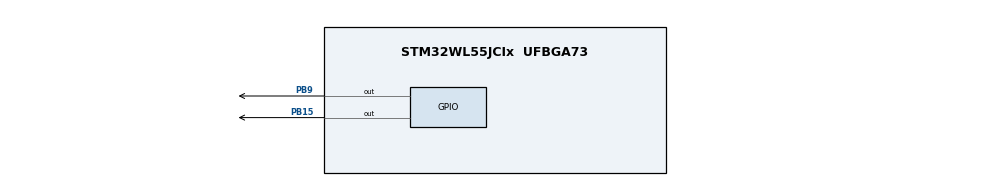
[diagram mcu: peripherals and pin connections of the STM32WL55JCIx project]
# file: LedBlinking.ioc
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Mcu.Family=STM32WL
Mcu.Name=STM32WL55JCIx
Mcu.Package=UFBGA73
NVIC.PriorityGroup=NVIC_PRIORITYGROUP_4
PB15.GPIO_Speed=GPIO_SPEED_FREQ_LOW
PB15.Signal=GPIO_Output
PB3.Signal=SPI1_SCK
PB9.Signal=GPIO_Output
ProjectManager.HeapSize=0x200
ProjectManager.StackSize=0x400
ProjectManager.TargetToolchain=STM32CubeIDE
RCC.AHBFreq_Value=48000000
RCC.APB1Freq_Value=48000000
RCC.APB1TimFreq_Value=48000000
RCC.APB2Freq_Value=48000000
RCC.APB2TimFreq_Value=48000000
RCC.APB3Freq_Value=48000000
RCC.CortexFreq_Value=48000000
RCC.HCLKFreq_Value=48000000
RCC.HSE_VALUE=8000000
RCC.HSI_VALUE=16000000
RCC.LSE_VALUE=32768
RCC.MSIClockRange=RCC_MSIRANGE_11
RCC.SYSCLKFreq_VALUE=48000000
RCC.VCOOutputFreq_Value=384000000
board=custom

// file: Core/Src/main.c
/* USER CODE BEGIN Header */
/**
  ******************************************************************************
  * @file           : main.c
  * @brief          : Main program body
  ******************************************************************************
  * @attention
  *
  * <h2><center>&copy; Copyright (c) 2021 STMicroelectronics.
  * All rights reserved.</center></h2>
  *
  * This software component is licensed by ST under BSD 3-Clause license,
  * the "License"; You may not use this file except in compliance with the
  * License. You may obtain a copy of the License at:
  *                        opensource.org/licenses/BSD-3-Clause
  *
  ******************************************************************************
  */
/* USER CODE END Header */
#include "main.h"

void SystemClock_Config(void);
static void MX_GPIO_Init(void);

int main(void)
{

  /* MCU Configuration--------------------------------------------------------*/

  /* Reset of all peripherals, Initializes the Flash interface and the Systick. */
  HAL_Init();

  /* Configure the system clock */
  SystemClock_Config();

  /* Initialize all configured peripherals */
  MX_GPIO_Init();

  /* Infinite loop */
  while (1)
  {

    /* USER CODE BEGIN 3 */

	HAL_GPIO_TogglePin(GPIOB,GPIO_PIN_15);
	HAL_GPIO_TogglePin(GPIOB,GPIO_PIN_9);
	HAL_Delay(500);
  }
  /* USER CODE END 3 */
}

void SystemClock_Config(void)
{
  RCC_OscInitTypeDef RCC_OscInitStruct = {0};
  RCC_ClkInitTypeDef RCC_ClkInitStruct = {0};

  /** Configure the main internal regulator output voltage
  */
  __HAL_PWR_VOLTAGESCALING_CONFIG(PWR_REGULATOR_VOLTAGE_SCALE1);
  /** Initializes the CPU, AHB and APB busses clocks
  */
  RCC_OscInitStruct.OscillatorType = RCC_OSCILLATORTYPE_MSI;
  RCC_OscInitStruct.MSIState = RCC_MSI_ON;
  RCC_OscInitStruct.MSICalibrationValue = RCC_MSICALIBRATION_DEFAULT;
  RCC_OscInitStruct.MSIClockRange = RCC_MSIRANGE_11;
  RCC_OscInitStruct.PLL.PLLState = RCC_PLL_NONE;
  if (HAL_RCC_OscConfig(&RCC_OscInitStruct) != HAL_OK)
  {
    Error_Handler();
  }
  /** Configure the SYSCLKSource, HCLK, PCLK1 and PCLK2 clocks dividers
  */
  RCC_ClkInitStruct.ClockType = RCC_CLOCKTYPE_HCLK3|RCC_CLOCKTYPE_HCLK
                              |RCC_CLOCKTYPE_SYSCLK|RCC_CLOCKTYPE_PCLK1
                              |RCC_CLOCKTYPE_PCLK2;
  RCC_ClkInitStruct.SYSCLKSource = RCC_SYSCLKSOURCE_MSI;
  RCC_ClkInitStruct.AHBCLKDivider = RCC_SYSCLK_DIV1;
  RCC_ClkInitStruct.APB1CLKDivider = RCC_HCLK_DIV1;
  RCC_ClkInitStruct.APB2CLKDivider = RCC_HCLK_DIV1;
  RCC_ClkInitStruct.AHBCLK3Divider = RCC_SYSCLK_DIV1;

  if (HAL_RCC_ClockConfig(&RCC_ClkInitStruct, FLASH_LATENCY_2) != HAL_OK)
  {
    Error_Handler();
  }
}

static void MX_GPIO_Init(void)
{
  GPIO_InitTypeDef GPIO_InitStruct = {0};

  /* GPIO Ports Clock Enable */
  __HAL_RCC_GPIOB_CLK_ENABLE();

  /*Configure GPIO pin Output Level */
  HAL_GPIO_WritePin(GPIOB, GPIO_PIN_15|GPIO_PIN_9, GPIO_PIN_RESET);

  /*Configure GPIO pins : PB15 PB9 */
  GPIO_InitStruct.Pin = GPIO_PIN_15|GPIO_PIN_9;
  GPIO_InitStruct.Mode = GPIO_MODE_OUTPUT_PP;
  GPIO_InitStruct.Pull = GPIO_NOPULL;
  GPIO_InitStruct.Speed = GPIO_SPEED_FREQ_LOW;
  HAL_GPIO_Init(GPIOB, &GPIO_InitStruct);

  /*Configure GPIO pin : PB3 */
  GPIO_InitStruct.Pin = GPIO_PIN_3;
  GPIO_InitStruct.Mode = GPIO_MODE_AF_PP;
  GPIO_InitStruct.Pull = GPIO_NOPULL;
  GPIO_InitStruct.Speed = GPIO_SPEED_FREQ_LOW;
  GPIO_InitStruct.Alternate = GPIO_AF5_SPI1;
  HAL_GPIO_Init(GPIOB, &GPIO_InitStruct);

}

void Error_Handler(void)
{
  __disable_irq();
  while (1)
  {
  }
}

/************************ (C) COPYRIGHT STMicroelectronics *****END OF FILE****/
